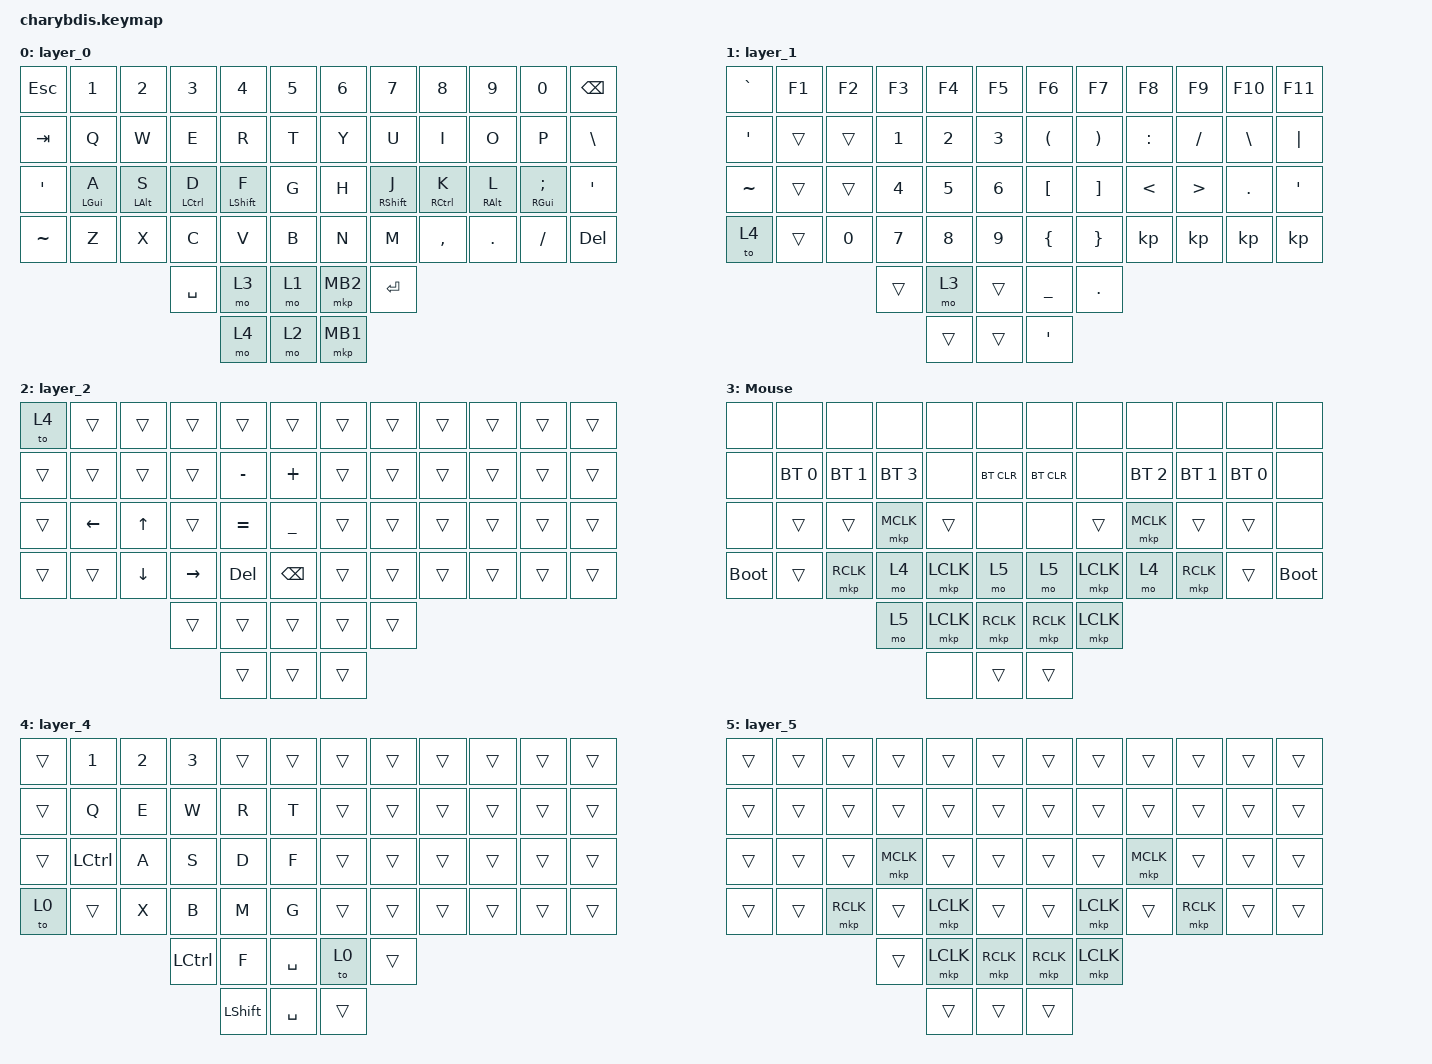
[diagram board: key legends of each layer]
#include <dt-bindings/zmk/mouse.h>
#include <behaviors.dtsi>
#include <dt-bindings/zmk/bt.h>
#include <dt-bindings/zmk/keys.h>
// #include <dt-bindings/zmk/pointing.h>

&lt {
    tapping-term-ms = <200>;
    flavor = "balanced";
    quick-tap-ms = <150>;
};

/ {
 
    keymap {
        compatible = "zmk,keymap";

        layer_0 {
            bindings = <
&kp ESC         &kp N1          &kp N2          &kp N3       &kp N4                &kp N5          &kp N6     &kp N7             &kp N8       &kp N9           &kp N0                   &kp BACKSPACE
&kp TAB         &kp Q           &kp W           &kp E        &kp R                 &kp T           &kp Y      &kp U              &kp I        &kp O            &kp P                    &kp BSLH
&kp APOS        &mt LEFT_GUI A  &mt LEFT_ALT S  &mt LCTRL D  &mt LEFT_SHIFT F      &kp G           &kp H      &mt RIGHT_SHIFT J  &mt RCTRL K  &mt RIGHT_ALT L  &mt RIGHT_GUI SEMICOLON  &kp SQT
&kp TILDE       &kp Z           &kp X           &kp C        &kp V                 &kp B           &kp N      &kp M              &kp COMMA    &kp DOT          &kp FSLH                 &kp DEL
                                                &kp SPACE    &mo 3                 &mo 1           &mkp MB2   &kp ENTER
                                                             &mo 4                 &mo 2           &mkp MB1
            >;

            trackball-bindings = <&tmv_coarse>;
        };

        layer_1 {
            bindings = <
&kp GRAVE  &kp F1  &kp F2  &kp F3       &kp F4     &kp F5      &kp F6                  &kp F7                 &kp F8     &kp F9   &kp F10     &kp F11
&kp APOS   &trans  &trans  &kp N1       &kp N2     &kp N3      &kp LEFT_PARENTHESIS    &kp RIGHT_PARENTHESIS  &kp COLON  &kp FSLH &kp BSLH    &kp PIPE 
&kp TILDE  &trans  &trans  &kp N4       &kp N5     &kp N6      &kp LEFT_BRACKET        &kp RIGHT_BRACKET      &kp LT     &kp GT   &kp DOT     &kp SQT 
&to 4      &trans  &kp N0  &kp N7       &kp N8     &kp N9      &kp LEFT_BRACE          &kp RIGHT_BRACE        &kp        &kp      &kp         &kp 
                           &trans       &mo 3      &trans      &kp UNDER               &kp DOT  
                                        &trans     &trans      &kp SINGLE_QUOTE
            >;

            trackball-bindings = <&tsl>;
        };

         layer_2 {
            bindings = <
&to 4     &trans          &trans         &trans           &trans       &trans         &trans   &trans     &trans      &trans            &trans  &trans
&trans    &trans          &trans         &trans           &kp MINUS    &kp PLUS       &trans   &trans     &trans      &trans            &trans  &trans
&trans    &kp LEFT_ARROW  &kp UP_ARROW   &trans           &kp EQUAL    &kp UNDER      &trans   &trans     &trans      &trans            &trans  &trans
&trans    &trans          &kp DOWN_ARROW &kp RIGHT_ARROW  &kp DEL      &kp BACKSPACE  &trans   &trans     &trans      &trans            &trans  &trans
                                         &trans           &trans    &trans         &trans   &trans 
                                                          &trans       &trans         &trans 
            >;
          trackball-bindings = <&tsl>;
            
        };

       Mouse {
            bindings = <
&none        &none         &none         &none         &none      &none         &none       &none      &none         &none         &none         &none
&none        &bt BT_SEL 0  &bt BT_SEL 1  &bt BT_SEL 3  &none      &bt BT_CLR    &bt BT_CLR  &none      &bt BT_SEL 2  &bt BT_SEL 1  &bt BT_SEL 0  &none
&none        &trans        &trans        &mkp MCLK     &trans     &none         &none       &trans     &mkp MCLK     &trans        &trans        &none
&bootloader  &trans        &mkp RCLK     &mo 4         &mkp LCLK  &mo 5         &mo 5       &mkp LCLK  &mo 4         &mkp RCLK     &trans        &bootloader
                                         &mo 5         &mkp LCLK  &mkp RCLK     &mkp RCLK   &mkp LCLK
                                                       &none      &trans        &trans
            >;

            
        };

        layer_4 {
            bindings = <
&trans  &kp N1     &kp N2    &kp N3     &trans          &trans       &trans           &trans     &trans     &trans     &trans  &trans
&trans  &kp Q      &kp E     &kp W      &kp R           &kp T        &trans           &trans     &trans     &trans     &trans  &trans
&trans  &kp LCTRL  &kp A     &kp S      &kp D           &kp F        &trans           &trans     &trans     &trans     &trans  &trans
&to 0   &trans     &kp X     &kp B      &kp M           &kp G        &trans           &trans     &trans     &trans     &trans  &trans
                             &kp LCTRL  &kp F           &kp SPACE    &to 0            &trans
                                        &kp LEFT_SHIFT  &kp SPACE    &trans
            >;
                
                
                trackball-bindings = <&tsl>;
        };

        layer_5 {
            bindings = <
&trans  &trans  &trans     &trans     &trans     &trans       &trans     &trans     &trans     &trans     &trans  &trans
&trans  &trans  &trans     &trans     &trans     &trans       &trans     &trans     &trans     &trans     &trans  &trans
&trans  &trans  &trans     &mkp MCLK  &trans     &trans       &trans     &trans     &mkp MCLK  &trans     &trans  &trans
&trans  &trans  &mkp RCLK  &trans     &mkp LCLK  &trans       &trans     &mkp LCLK  &trans     &mkp RCLK  &trans  &trans
                           &trans     &mkp LCLK  &mkp RCLK    &mkp RCLK  &mkp LCLK
                                      &trans     &trans       &trans
            >;
                trackball-bindings = <&tmv_fine>;
                
        };
    };
};
